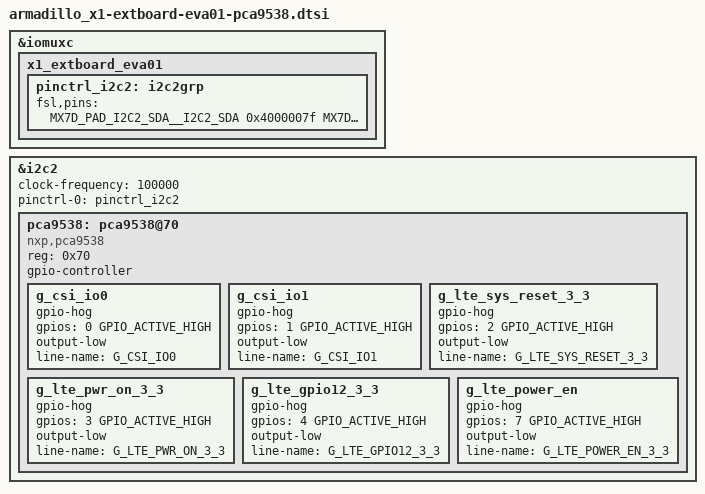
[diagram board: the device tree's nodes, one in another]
/*
 * Copyright (C) 2018 Atmark Techno, Inc. All Rights Reserved.
 *
 * This program is free software; you can redistribute it and/or modify
 * it under the terms of the GNU General Public License version 2 as
 * published by the Free Software Foundation.
 */
&iomuxc {
	x1_extboard_eva01 {
		pinctrl_i2c2: i2c2grp {
			fsl,pins = <
				MX7D_PAD_I2C2_SDA__I2C2_SDA	0x4000007f
				MX7D_PAD_I2C2_SCL__I2C2_SCL	0x4000007f
			>;
		};
	};
};

&i2c2 {
	clock-frequency = <100000>;
	pinctrl-names = "default";
	pinctrl-0 = <&pinctrl_i2c2>;
	status = "okay";

	pca9538: pca9538@70 {
		compatible = "nxp,pca9538";
		reg = <0x70>;
		gpio-controller;
		#gpio-cells = <2>;
	};
};

&pca9538 {
	g_csi_io0 {
		gpio-hog;
		gpios = <0 GPIO_ACTIVE_HIGH>;
		output-low;
		line-name = "G_CSI_IO0";
	};

	g_csi_io1 {
		gpio-hog;
		gpios = <1 GPIO_ACTIVE_HIGH>;
		output-low;
		line-name = "G_CSI_IO1";
	};

	g_lte_sys_reset_3_3 {
		gpio-hog;
		gpios = <2 GPIO_ACTIVE_HIGH>;
		output-low;
		line-name = "G_LTE_SYS_RESET_3_3";
	};

	g_lte_pwr_on_3_3 {
		gpio-hog;
		gpios = <3 GPIO_ACTIVE_HIGH>;
		output-low;
		line-name = "G_LTE_PWR_ON_3_3";
	};

	g_lte_gpio12_3_3 {
		gpio-hog;
		gpios = <4 GPIO_ACTIVE_HIGH>;
		output-low;
		line-name = "G_LTE_GPIO12_3_3";
	};

	g_lte_power_en {
		gpio-hog;
		gpios = <7 GPIO_ACTIVE_HIGH>;
		output-low;
		line-name = "G_LTE_POWER_EN_3_3";
	};
};
